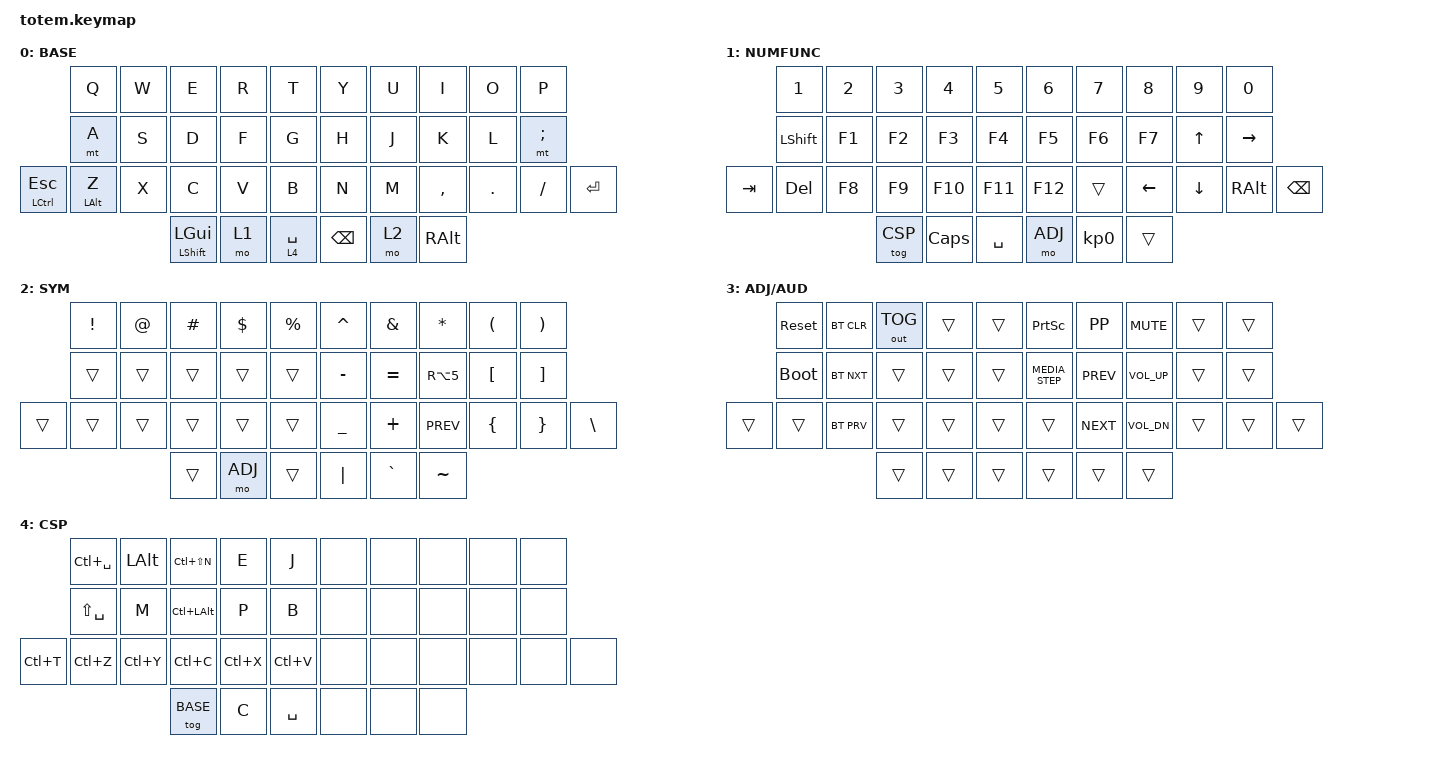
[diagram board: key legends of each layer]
//
//                                                        ▀▀▀▀▀     ▀▀▀▀▀          ▀▀█▀▀
//                                                        ▄▀▀▀▄  ▄  ▄▀▀▀▄  ▄  ▄▀▀▀▄  █  ▄▀▀▀▄
//                                                        █   █  █  █   █  █  █   █  █  █   █
//                                                         ▀▀▀   █   ▀▀▀   █   ▀▀▀   ▀   ▀▀▀
//                                                               █      ▄▄▄█▄▄▄    █   █  
//                                                               ▀      █  █  █     █▄█
//                                                             ▀▀▀▀▀    █  █  █      ▀
//                                                                      ▀  ▀  ▀
//
// ▄▄▄▄▄▄▄▄▄▄▄▄▄▄▄▄▄▄▄▄▄▄▄▄▄▄▄▄▄▄▄▄▄▄▄▄▄▄▄▄▄▄▄▄▄▄▄▄▄▄▄▄▄▄▄▄▄▄▄▄▄▄▄▄▄▄▄▄▄▄▄▄▄▄▄▄▄▄▄▄▄▄▄▄▄▄▄▄▄▄▄▄▄▄▄▄▄▄▄▄▄▄▄▄▄▄▄▄▄▄▄▄▄▄▄▄▄▄▄▄▄▄▄▄▄▄▄▄▄▄▄▄▄▄▄▄▄▄▄▄▄▄▄▄▄▄▄▄▄
       

#include <behaviors.dtsi>
#include <dt-bindings/zmk/keys.h>
#include <dt-bindings/zmk/bt.h>
#include <dt-bindings/zmk/outputs.h>

#define BASE 0
#define NUMFUNC  1
#define SYM  2
#define ADJ_AUD  3
#define CSP 4

&mt {
  quick-tap-ms = <100>;
  global-quick-tap;
  flavor = "tap-preferred";
  tapping-term-ms = <170>;
};

/ {
     combos {
            compatible = "zmk,combos";
    };

    macros {

    };

        keymap {
                compatible = "zmk,keymap";
// ▄▄▄▄▄▄▄▄▄▄▄▄▄▄▄▄▄▄▄▄▄▄▄▄▄▄▄▄▄▄▄▄▄▄▄▄▄▄▄▄▄▄▄▄▄▄▄▄▄▄▄▄▄▄▄▄▄▄▄▄▄▄▄▄▄▄▄▄▄▄▄▄▄▄▄▄▄▄▄▄▄▄▄▄▄▄▄▄▄▄▄▄▄▄▄▄▄▄▄▄▄▄▄▄▄▄▄▄▄▄▄▄▄▄▄▄▄▄▄▄▄▄▄▄▄▄▄▄▄▄▄▄▄▄▄▄▄▄▄▄▄▄▄▄▄▄▄▄▄

                base_layer {
// ┏━━━━━━━━━━━━━━━━━━━━━━━━━━━━━━━━━━━━━━━┓
label= "BASE"                              ;
// ┗━━━━━━━━━━━━━━━━━━━━━━━━━━━━━━━━━━━━━━━┛
//             ┏━━━━━━━━━━━┳━━━━━━━━━━━┳━━━━━━━━━━━┳━━━━━━━━━━━┳━━━━━━━━━━━┓   ┏━━━━━━━━━━━┳━━━━━━━━━━━┳━━━━━━━━━━━┳━━━━━━━━━━━┳━━━━━━━━━━━┓
//             ┃     Q     ┃     W     ┃     E     ┃     R     ┃     T     ┃   ┃     Y     ┃     U     ┃     I     ┃     O     ┃     P     ┃
//             ┣━━━━━━━━━━━╋━━━━━━━━━━━╋━━━━━━━━━━━╋━━━━━━━━━━━╋━━━━━━━━━━━┫   ┣━━━━━━━━━━━╋━━━━━━━━━━━╋━━━━━━━━━━━╋━━━━━━━━━━━╋━━━━━━━━━━━┫
//             ┃     A     ┃     S     ┃     D     ┃     F     ┃     G     ┃   ┃     H     ┃     J     ┃     K     ┃     L     ┃     ;:    ┃
// ┏━━━━━━━━━━━╋━━━━━━━━━━━╋━━━━━━━━━━━╋━━━━━━━━━━━╋━━━━━━━━━━━╋━━━━━━━━━━━┫   ┣━━━━━━━━━━━╋━━━━━━━━━━━╋━━━━━━━━━━━╋━━━━━━━━━━━╋━━━━━━━━━━━╋━━━━━━━━━━━┓
// ┃  ESC/CTRL ┃   LALT/Z  ┃     X     ┃     C     ┃     V     ┃     B     ┃   ┃     N     ┃     M     ┃     ,<    ┃     .>    ┃     /?    ┃   ENTER   ┃
// ┗━━━━━━━━━━━┻━━━━━━━━━━━┻━━━━━━━━━━━╋━━━━━━━━━━━╋━━━━━━━━━━━╋━━━━━━━━━━━┫   ┣━━━━━━━━━━━╋━━━━━━━━━━━╋━━━━━━━━━━━╋━━━━━━━━━━━┻━━━━━━━━━━━┻━━━━━━━━━━━┛
//                                     ┃ SHIFT/WIN ┃    LAY1   ┃    SPC    ┃   ┃    BSPC   ┃    LAY2   ┃   RALT    ┃
//                                     ┗━━━━━━━━━━━┻━━━━━━━━━━━┻━━━━━━━━━━━┛   ┗━━━━━━━━━━━┻━━━━━━━━━━━┻━━━━━━━━━━━┛
 bindings = <
// ╷               ╷           ╷           ╷               ╷           ╷           ╷   ╷           ╷           ╷           ╷           ╷           ╷           ╷

                    &kp Q       &kp W       &kp E           &kp R       &kp T           &kp Y       &kp U       &kp I       &kp O       &kp P
                    &mt A       &kp S       &kp D           &kp F       &kp G           &kp H       &kp J       &kp K       &kp L       &mt SEMI
    &mt LCTRL ESC   &mt LALT Z  &kp X       &kp C           &kp V       &kp B           &kp N       &kp M       &kp COMMA   &kp DOT     &kp FSLH    &kp RET
                                            &mt LSHFT LGUI  &mo 1       &lt 4 SPACE     &kp BSPC    &mo 2       &kp RALT
                        >;
                };

// ▄▄▄▄▄▄▄▄▄▄▄▄▄▄▄▄▄▄▄▄▄▄▄▄▄▄▄▄▄▄▄▄▄▄▄▄▄▄▄▄▄▄▄▄▄▄▄▄▄▄▄▄▄▄▄▄▄▄▄▄▄▄▄▄▄▄▄▄▄▄▄▄▄▄▄▄▄▄▄▄▄▄▄▄▄▄▄▄▄▄▄▄▄▄▄▄▄▄▄▄▄▄▄▄▄▄▄▄▄▄▄▄▄▄▄▄▄▄▄▄▄▄▄▄▄▄▄▄▄▄▄▄▄▄▄▄▄▄▄▄▄▄▄▄▄▄▄▄▄


                nav_layer {
// ┏━━━━━━━━━━━━━━━━━━━━━━━━━━━━━━━━━━━━━━━┓
label= "NUMFUNC"                           ;
// ┗━━━━━━━━━━━━━━━━━━━━━━━━━━━━━━━━━━━━━━━┛
//             ┏━━━━━━━━━━━┳━━━━━━━━━━━┳━━━━━━━━━━━┳━━━━━━━━━━━┳━━━━━━━━━━━┓   ┏━━━━━━━━━━━┳━━━━━━━━━━━┳━━━━━━━━━━━┳━━━━━━━━━━━┳━━━━━━━━━━━┓
//             ┃     1     ┃     2     ┃     3     ┃     4     ┃     5     ┃   ┃     6     ┃     7     ┃     8     ┃     9     ┃     0     ┃
//             ┣━━━━━━━━━━━╋━━━━━━━━━━━╋━━━━━━━━━━━╋━━━━━━━━━━━╋━━━━━━━━━━━┫   ┣━━━━━━━━━━━╋━━━━━━━━━━━╋━━━━━━━━━━━╋━━━━━━━━━━━╋━━━━━━━━━━━┫
//             ┃   SHIFT   ┃     F1    ┃    F2     ┃    F3     ┃    F4     ┃   ┃     F5    ┃    F6     ┃    F7     ┃     UP    ┃   RIGHT   ┃
// ┏━━━━━━━━━━━╋━━━━━━━━━━━╋━━━━━━━━━━━╋━━━━━━━━━━━╋━━━━━━━━━━━╋━━━━━━━━━━━┫   ┣━━━━━━━━━━━╋━━━━━━━━━━━╋━━━━━━━━━━━╋━━━━━━━━━━━╋━━━━━━━━━━━╋━━━━━━━━━━━┓
// ┃    TAB    ┃    LALT   ┃    F8     ┃    F9     ┃    F10    ┃    F11    ┃   ┃    F12    ┃           ┃    LEFT   ┃    DOWN   ┃    RALT   ┃   BSPC    ┃
// ┗━━━━━━━━━━━┻━━━━━━━━━━━┻━━━━━━━━━━━╋━━━━━━━━━━━╋━━━━━━━━━━━╋━━━━━━━━━━━┫   ┣━━━━━━━━━━━╋━━━━━━━━━━━╋━━━━━━━━━━━╋━━━━━━━━━━━┻━━━━━━━━━━━┻━━━━━━━━━━━┛
//                                     ┃    CSP    ┃    CAPS   ┃    SPC    ┃   ┃    HOME   ┃    LAY3   ┃    END    ┃
//                                     ┗━━━━━━━━━━━┻━━━━━━━━━━━┻━━━━━━━━━━━┛   ┗━━━━━━━━━━━┻━━━━━━━━━━━┻━━━━━━━━━━━┛
 bindings = <
// ╷           ╷           ╷           ╷           ╷           ╷           ╷   ╷           ╷           ╷           ╷           ╷           ╷           ╷

                &kp N1      &kp N2      &kp N3      &kp N4      &kp N5          &kp N6      &kp N7      &kp N8      &kp N9      &kp N0
                &kp LSHFT   &kp F1      &kp F2      &kp F3      &kp F4          &kp F5      &kp F6      &kp F7      &kp UP      &kp RIGHT
    &kp TAB     &kp DEL     &kp F8      &kp F9      &kp F10     &kp F11         &kp F12     &trans      &kp LEFT    &kp DOWN    &kp RALT    &kp BSPC      
                                        &tog CSP    &kp CAPS      &kp SPACE          &mo ADJ     &kp KP_N0   &trans      
                        >;
                };

// ▄▄▄▄▄▄▄▄▄▄▄▄▄▄▄▄▄▄▄▄▄▄▄▄▄▄▄▄▄▄▄▄▄▄▄▄▄▄▄▄▄▄▄▄▄▄▄▄▄▄▄▄▄▄▄▄▄▄▄▄▄▄▄▄▄▄▄▄▄▄▄▄▄▄▄▄▄▄▄▄▄▄▄▄▄▄▄▄▄▄▄▄▄▄▄▄▄▄▄▄▄▄▄▄▄▄▄▄▄▄▄▄▄▄▄▄▄▄▄▄▄▄▄▄▄▄▄▄▄▄▄▄▄▄▄▄▄▄▄▄▄▄▄▄▄▄▄▄▄


                sim_layer {
// ┏━━━━━━━━━━━━━━━━━━━━━━━━━━━━━━━━━━━━━━━┓
label= "SYM"                               ;
// ┗━━━━━━━━━━━━━━━━━━━━━━━━━━━━━━━━━━━━━━━┛
//             ┏━━━━━━━━━━━┳━━━━━━━━━━━┳━━━━━━━━━━━┳━━━━━━━━━━━┳━━━━━━━━━━━┓   ┏━━━━━━━━━━━┳━━━━━━━━━━━┳━━━━━━━━━━━┳━━━━━━━━━━━┳━━━━━━━━━━━┓
//             ┃     !     ┃     @     ┃     #     ┃     $     ┃     %     ┃   ┃     ˆ     ┃     &     ┃     *     ┃     (     ┃     )     ┃
//             ┣━━━━━━━━━━━╋━━━━━━━━━━━╋━━━━━━━━━━━╋━━━━━━━━━━━╋━━━━━━━━━━━┫   ┣━━━━━━━━━━━╋━━━━━━━━━━━╋━━━━━━━━━━━╋━━━━━━━━━━━╋━━━━━━━━━━━┫
//             ┃           ┃           ┃           ┃           ┃           ┃   ┃     -     ┃     =     ┃     '     ┃     [     ┃     ]     ┃
// ┏━━━━━━━━━━━╋━━━━━━━━━━━╋━━━━━━━━━━━╋━━━━━━━━━━━╋━━━━━━━━━━━╋━━━━━━━━━━━┫   ┣━━━━━━━━━━━╋━━━━━━━━━━━╋━━━━━━━━━━━╋━━━━━━━━━━━╋━━━━━━━━━━━╋━━━━━━━━━━━┓
// ┃           ┃           ┃           ┃           ┃           ┃           ┃   ┃     _     ┃     +     ┃     "     ┃     {     ┃     }     ┃     \     ┃
// ┗━━━━━━━━━━━┻━━━━━━━━━━━┻━━━━━━━━━━━╋━━━━━━━━━━━╋━━━━━━━━━━━╋━━━━━━━━━━━┫   ┣━━━━━━━━━━━╋━━━━━━━━━━━╋━━━━━━━━━━━╋━━━━━━━━━━━┻━━━━━━━━━━━┻━━━━━━━━━━━┛
//                                     ┃           ┃    LAY3   ┃           ┃   ┃     |     ┃     `     ┃     ~     ┃
//                                     ┗━━━━━━━━━━━┻━━━━━━━━━━━┻━━━━━━━━━━━┛   ┗━━━━━━━━━━━┻━━━━━━━━━━━┻━━━━━━━━━━━┛
 bindings = <
// ╷           ╷           ╷           ╷           ╷           ╷           ╷   ╷           ╷           ╷           ╷           ╷           ╷           ╷

                &kp EXCL    &kp AT      &kp HASH    &kp DLLR    &kp PRCNT       &kp CARET   &kp AMPS    &kp ASTRK   &kp LPAR    &kp RPAR       
                &trans      &trans      &trans      &trans      &trans          &kp MINUS   &kp EQUAL   &kp RA(N5)  &kp LBKT    &kp RBKT 
    &trans      &trans      &trans      &trans      &trans      &trans          &kp UNDER   &kp PLUS    &kp C_PREV  &kp LBRC    &kp RBRC    &kp BSLH         
                                        &trans      &mo ADJ     &trans          &kp PIPE    &kp GRAVE   &kp TILDE      
                        >;
                };

// ▄▄▄▄▄▄▄▄▄▄▄▄▄▄▄▄▄▄▄▄▄▄▄▄▄▄▄▄▄▄▄▄▄▄▄▄▄▄▄▄▄▄▄▄▄▄▄▄▄▄▄▄▄▄▄▄▄▄▄▄▄▄▄▄▄▄▄▄▄▄▄▄▄▄▄▄▄▄▄▄▄▄▄▄▄▄▄▄▄▄▄▄▄▄▄▄▄▄▄▄▄▄▄▄▄▄▄▄▄▄▄▄▄▄▄▄▄▄▄▄▄▄▄▄▄▄▄▄▄▄▄▄▄▄▄▄▄▄▄▄▄▄▄▄▄▄▄▄▄


                adjust_layer {
// ┏━━━━━━━━━━━━━━━━━━━━━━━━━━━━━━━━━━━━━━━┓
label= "ADJ/AUD"                           ;
// ┗━━━━━━━━━━━━━━━━━━━━━━━━━━━━━━━━━━━━━━━┛
//             ┏━━━━━━━━━━━┳━━━━━━━━━━━┳━━━━━━━━━━━┳━━━━━━━━━━━┳━━━━━━━━━━━┓   ┏━━━━━━━━━━━┳━━━━━━━━━━━┳━━━━━━━━━━━┳━━━━━━━━━━━┳━━━━━━━━━━━┓
//             ┃   RESET   ┃ BT CLEAR  ┃  OUT TOG  ┃           ┃           ┃   ┃   PSCRN   ┃    K_PP   ┃   C_MUTE  ┃           ┃           ┃
//             ┣━━━━━━━━━━━╋━━━━━━━━━━━╋━━━━━━━━━━━╋━━━━━━━━━━━╋━━━━━━━━━━━┫   ┣━━━━━━━━━━━╋━━━━━━━━━━━╋━━━━━━━━━━━╋━━━━━━━━━━━╋━━━━━━━━━━━┫
//             ┃ BOOTLOAD  ┃ BT NEXT   ┃           ┃           ┃           ┃   ┃ MEDIASTEP ┃   C_PREV  ┃    VOL+   ┃           ┃           ┃
// ┏━━━━━━━━━━━╋━━━━━━━━━━━╋━━━━━━━━━━━╋━━━━━━━━━━━╋━━━━━━━━━━━╋━━━━━━━━━━━┫   ┣━━━━━━━━━━━╋━━━━━━━━━━━╋━━━━━━━━━━━╋━━━━━━━━━━━╋━━━━━━━━━━━╋━━━━━━━━━━━┓
// ┃           ┃           ┃ BT PREV   ┃           ┃           ┃           ┃   ┃           ┃   C_NEXT  ┃    VOL-   ┃           ┃           ┃           ┃
// ┗━━━━━━━━━━━┻━━━━━━━━━━━┻━━━━━━━━━━━╋━━━━━━━━━━━╋━━━━━━━━━━━╋━━━━━━━━━━━┫   ┣━━━━━━━━━━━╋━━━━━━━━━━━╋━━━━━━━━━━━╋━━━━━━━━━━━┻━━━━━━━━━━━┻━━━━━━━━━━━┛
//                                     ┃           ┃           ┃           ┃   ┃           ┃           ┃           ┃
//                                     ┗━━━━━━━━━━━┻━━━━━━━━━━━┻━━━━━━━━━━━┛   ┗━━━━━━━━━━━┻━━━━━━━━━━━┻━━━━━━━━━━━┛
 bindings = <
// ╷           ╷           ╷           ╷           ╷           ╷           ╷   ╷                 ╷           ╷           ╷           ╷           ╷           ╷

                &sys_reset  &bt BT_CLR &out OUT_TOG &trans      &trans          &kp PSCRN         &kp K_PP    &kp C_MUTE      &trans      &trans
                &bootloader &bt BT_NXT  &trans      &trans      &trans          &kp C_MEDIA_STEP  &kp C_PREV  &kp C_VOL_UP    &trans      &trans  
    &trans      &trans      &bt BT_PRV  &trans      &trans      &trans          &trans            &kp C_NEXT  &kp C_VOL_DN    &trans      &trans     &trans         
                                        &trans      &trans      &trans          &trans            &trans      &trans      
                        >;
                };

// ▄▄▄▄▄▄▄▄▄▄▄▄▄▄▄▄▄▄▄▄▄▄▄▄▄▄▄▄▄▄▄▄▄▄▄▄▄▄▄▄▄▄▄▄▄▄▄▄▄▄▄▄▄▄▄▄▄▄▄▄▄▄▄▄▄▄▄▄▄▄▄▄▄▄▄▄▄▄▄▄▄▄▄▄▄▄▄▄▄▄▄▄▄▄▄▄▄▄▄▄▄▄▄▄▄▄▄▄▄▄▄▄▄▄▄▄▄▄▄▄▄▄▄▄▄▄▄▄▄▄▄▄▄▄▄▄▄▄▄▄▄▄▄▄▄▄▄▄▄


                csp_layer {
// ┏━━━━━━━━━━━━━━━━━━━━━━━━━━━━━━━━━━━━━━━┓
label= "CSP"                             ;
// ┗━━━━━━━━━━━━━━━━━━━━━━━━━━━━━━━━━━━━━━━┛
//             ┏━━━━━━━━━━━┳━━━━━━━━━━━┳━━━━━━━━━━━┳━━━━━━━━━━━┳━━━━━━━━━━━┓   ┏━━━━━━━━━━━┳━━━━━━━━━━━┳━━━━━━━━━━━┳━━━━━━━━━━━┳━━━━━━━━━━━┓
//             ┃   ZOOM    ┃  COLPICK  ┃   NEWLAY  ┃   ERASER  ┃   BLEND   ┃   ┃           ┃           ┃           ┃           ┃           ┃
//             ┣━━━━━━━━━━━╋━━━━━━━━━━━╋━━━━━━━━━━━╋━━━━━━━━━━━╋━━━━━━━━━━━┫   ┣━━━━━━━━━━━╋━━━━━━━━━━━╋━━━━━━━━━━━╋━━━━━━━━━━━╋━━━━━━━━━━━┫
//             ┃   ROTATE  ┃   SELECT  ┃   BSIZE   ┃    PEN    ┃   BRUSH   ┃   ┃           ┃           ┃           ┃           ┃           ┃
// ┏━━━━━━━━━━━╋━━━━━━━━━━━╋━━━━━━━━━━━╋━━━━━━━━━━━╋━━━━━━━━━━━╋━━━━━━━━━━━┫   ┣━━━━━━━━━━━╋━━━━━━━━━━━╋━━━━━━━━━━━╋━━━━━━━━━━━╋━━━━━━━━━━━╋━━━━━━━━━━━┓
// ┃ TRANSFORM ┃   UNDO    ┃   REDO    ┃    COPY   ┃    CUT    ┃   PASTE   ┃   ┃           ┃           ┃           ┃           ┃           ┃           ┃
// ┗━━━━━━━━━━━┻━━━━━━━━━━━┻━━━━━━━━━━━╋━━━━━━━━━━━╋━━━━━━━━━━━╋━━━━━━━━━━━┫   ┣━━━━━━━━━━━╋━━━━━━━━━━━╋━━━━━━━━━━━╋━━━━━━━━━━━┻━━━━━━━━━━━┻━━━━━━━━━━━┛
//                                     ┃   BASE    ┃  TRANSCOL ┃   MOVE    ┃   ┃           ┃           ┃           ┃
//                                     ┗━━━━━━━━━━━┻━━━━━━━━━━━┻━━━━━━━━━━━┛   ┗━━━━━━━━━━━┻━━━━━━━━━━━┻━━━━━━━━━━━┛
 bindings = <
// ╷           ╷               ╷           ╷              ╷           ╷           ╷   ╷           ╷           ╷           ╷           ╷           ╷           ╷

                &kp LC(SPACE)   &kp LALT    &kp LC(LS(N)) &kp E       &kp J           &none       &none       &none       &none       &none
                &kp LS(SPACE)   &kp M       &kp LC(LALT)  &kp P       &kp B           &none       &none       &none       &none       &none
    &kp LC(T)   &kp LC(Z)       &kp LC(Y)   &kp LC(C)     &kp LC(X)   &kp LC(V)       &none       &none       &none       &none       &none       &none        
                                            &tog BASE     &kp C       &kp SPACE       &none       &none       &none    
                        >;
                };
        };
};
